# STM32U5A5 register map
File version: 1.8
CPU: CM33 r0p1, little endian, MPU, FPU, 4 interrupt priority bits
Registers are 32-bit, read-write, reset 0x0 unless marked. A register's access mark holds for its fields unless they carry their own. Offsets are from the block's base; [hi:lo] are bit positions; {n}, {i} and the like mark numbered series; 'fields as' and 'values as' point back to an identical list.

## GPDMA1 (part 2 of 2)
Base 0x40020000
Same registers: SEC_GPDMA1 0x50020000
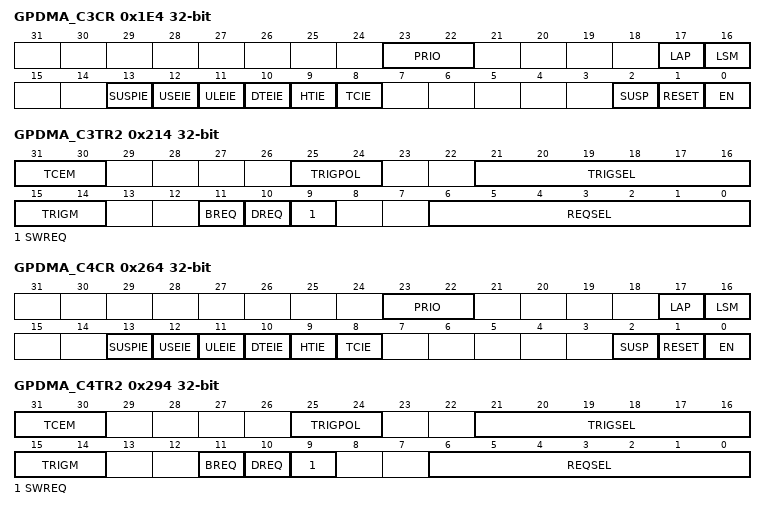
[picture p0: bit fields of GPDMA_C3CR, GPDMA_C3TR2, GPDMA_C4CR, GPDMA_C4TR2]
0x1E4 GPDMA_C3CR — channel x control register
  [23:22] PRIO — priority level of the DMA transfer of the channel x vs others- 00: low priority, low weight- 01: low priority, mid weight- 10: low priority, high weight- 11: high priorityNote: This bit must be written when EN=0. This bit is read-only when EN=1.
  [17] LAP — linked-list allocated portAllocate the master port for the update of the DMA linked-list registers from the memory.- 0: port 0 (AHB) is allocated for the update of the DMA linked-list channel x registers- 1: port 1 (AHB) is allocated for the update of the DMA linked-list channel x registersNote: This bit must be written when EN=0. This bit is read-only when EN=1.
  [16] LSM — Link Step mode:- 0: channel is executed for the full linked-list, and completed at the end (if any) of the last LLI i.e. when GPDMA_CxLLR=0: the 16 low significant bits of the link address are null (LA[15:0]=0) and all the update bits are null i.e. UT1=UB1=UT2=USA=UDA=UB2 =UT3=ULL=0. Then GPDMA_CxBR1.BRC[10:0]=0 and GPDMA_CxBR1.BNDT[15:0]=0.- 1: channel is executed once for the current LLI:* First the (possibly 2D/repeated) block transfer is executed as defined by the current internal register file until that (GPDMA_CxBR1.BRC[10:0]=0 and GPDMA_CxBR1.BNDT[15:0]=0).* Secondly the next linked-list data structure is conditionally uploaded from memory as defined by GPDMA_CxLLR register. Then channel execution is completed.Note: This bit must be written when EN=0. This bit is read-only when EN=1.
  [13] SUSPIE — completed suspension interrupt enable - 0: interrupt disabled - 1: interrupt enabled
  [12] USEIE — user setting error interrupt enable - 0: interrupt disabled - 1: interrupt enabled
  [11] ULEIE — update link transfer error interrupt enable - 0: interrupt disabled - 1: interrupt enabled
  [10] DTEIE — data transfer error interrupt enable - 0: interrupt disabled - 1: interrupt enabled
  [9] HTIE — half transfer complete interrupt enable - 0: interrupt disabled - 1: interrupt enabled
  [8] TCIE — transfer complete interrupt enable - 0: interrupt disabled - 1: interrupt enabled
  [2] SUSP — suspend - 0: write: resume channel, read: channel not suspended - 1: write: suspend channel, read: channel suspended Writing 1 into the field RESET (bit 1) causes the hardware to de-assert this bit, whatever is written into this bit 2. Else: Software must write 1 in order to suspend an active channel i.e. a channel with an on-going DMA transfer over its master ports. Software must write 0 in order to resume a suspended channel, following the programming sequence in Figure 3: DMA channel suspend and resume sequence.
  [1] RESET — reset - 0: no channel reset - 1: channel reset This bit is write only. Writing 0 has no impact. Writing 1 implies/will imply the reset of the FIFO, the reset of the channel internal state, and the reset of the SUSP and EN bits, whatever is written in respectively bit 2 and bit 0. The reset is/will be effective when the channel. i.e. either i) the active channel is in suspended state (i.e. GPDMA_CxSR.SUSPF=1 and GPDMA_CxSR.IDLEF=1 and GPDMA_CxCR.EN=1) or ii) the channel is in disabled state (i.e. GPDMA_CxSR.IDLEF=1 and GPDMA_CxCR.EN=0). After writing a RESET, if the user wants to continue using this channel, the user should explicitly reconfigure the channel including the hardware-modified configuration registers GPDMA_CxBR1, GPDMA_CxSAR and GPDMA_CxDAR, before enabling again the channel. Following the programming sequence in Figure 4: DMA channel abort and restart sequence.
  [0] EN — enable - 0: write: ignored, read: channel disabled - 1: write: enable channel, read: channel enabled Writing 1 into the field RESET (bit 1) causes the hardware to de-assert this bit, whatever is written into this bit 0. Else: * this bit is de-asserted by hardware when there is a transfer error (master bus error or user setting error) or when there is a channel transfer complete (channel ready to be configured, e.g. if LSM=1 at the end of a single execution of the LLI). * Else, this bit can be asserted by software. Writing 0 into this EN bit is ignored.
0x214 GPDMA_C3TR2 — GPDMA channel x transfer register 2
  [31:30] TCEM — Transfer complete event mode Defines the transfer granularity for the transfer complete (and half transfer complete) event generation. - 00: at block level (i.e. when GPDMA_CxBR1.BNDT[15:0]= 0): the complete (and the half) transfer event is generated at the (respectively half of the) end of a block. Note: If the initial LLI0 data transfer is null/void (i.e. directly programmed by the internal register file with GPDMA_CxBR1.BNDT[15:0]=0), then neither the complete transfer event nor the half transfer event is generated. - 01: channel x=0 to 11: same as 00 ;channel x=12 to 15: at 2D/repeated block level (i.e. when GPDMA_CxBR1.BRC[10:0]= 0 and GPDMA_CxBR1.BNDT[15:0]= 0): the complete (and the half) transfer event is generated at the end (respectively half of the end) of the 2D/repeated block Note: If the initial LLI0 data transfer is null/void (i.e. directly programmed by the internal register file with GPDMA_CxBR1.BNDT[15:0]=0), then neither the complete transfer event nor the half transfer event is generated. - 10: at LLI level: the complete transfer event is generated at the end of the LLI transfer, including the update of the LLI if any. The half transfer event is generated at the half of the LLI data transfer (the LLI data transfer being a block or a 2D/repeated block transfer), if any data transfer. Note: If the initial LLI0 data transfer is null/void (i.e. directly programmed by the internal register file with GPDMA_CxBR1.BNDT[15:0]=0), then the half transfer event is not generated, and the transfer complete event is generated when is completed the loading of the LLI1. - 11: at channel level: the complete transfer event is generated at the end of the last LLI transfer. The half transfer event is generated at the half of the data transfer of the last LLI. The last LLI is the one that updates the link address GPDMA_CxLLR.LA[15:2] to zero and that clears all the update bits - UT1, UT2, UB1, USA, UDA, if present UT3, UB2 and ULL - of the GPDMA_CxLLR register. If the channel transfer is continuous/infinite, no event is generated.
  [25:24] TRIGPOL — Trigger event polarity Defines the polarity of the selected trigger event input defined by TRIGSEL[5:0]. - 00: no trigger. Masked trigger event. - 01: trigger on the rising edge - 10: trigger on the falling edge - 11: same as 00
  [21:16] TRIGSEL — Trigger event input selection Note: Selects the trigger event input as per Table 13 of the DMA transfer, with an active trigger event if TRIGPOL[1:0] !=00.
  [15:14] TRIGM — Trigger mode
  [11] BREQ
  [10] DREQ — Destination hardware request If the channel x is activated (i.e. GPDMA_CxCR.EN is asserted) with SWREQ=1 (i.e. software request for a memory-to-memory transfer), this bit is ignored. Else: - 0: the selected hardware request is driven by a source peripheral (i.e. this request signal is taken into account by the DMA transfer scheduler over the source/read port) - 1: the selected hardware request is driven by a destination peripheral (.e. this request signal is taken into account by the DMA transfer scheduler over the destination/write port)
  [9] SWREQ — Software request When GPDMA_CxCR.EN is asserted, this field is internally taken into account: - 0: no software request. The selected hardware request REQSEL[6:0] is taken into account. - 1: software request (for a memory-to-memory transfer). And the default selected hardware request as per REQSEL[6:0] is ignored.
  [6:0] REQSEL — DMA hardware request selection If the channel x is activated (i.e. GPDMA_CxCR.EN is asserted) with SWREQ=1 (i.e. software request for a memory-to-memory transfer), this bit is ignored. Else, the selected hardware request as per Table 12 is internally taken into account. Note: The user must not assign a same input hardware request (i.e. a same REQSEL[6:0] value) to different active DMA channels (i.e. if GPDMA_CxCR.EN=1 and GPDMA_CxTR2.SWREQ=0 for the related x channels). In other words, DMA is not intended to hardware support the case of simultaneous enabled channels having been -incorrectly- configured with a same hardware peripheral request signal, and there is no user setting error reporting.
0x264 GPDMA_C4CR — channel x control register
  [23:22] PRIO — priority level of the DMA transfer of the channel x vs others- 00: low priority, low weight- 01: low priority, mid weight- 10: low priority, high weight- 11: high priorityNote: This bit must be written when EN=0. This bit is read-only when EN=1.
  [17] LAP — linked-list allocated portAllocate the master port for the update of the DMA linked-list registers from the memory.- 0: port 0 (AHB) is allocated for the update of the DMA linked-list channel x registers- 1: port 1 (AHB) is allocated for the update of the DMA linked-list channel x registersNote: This bit must be written when EN=0. This bit is read-only when EN=1.
  [16] LSM — Link Step mode:- 0: channel is executed for the full linked-list, and completed at the end (if any) of the last LLI i.e. when GPDMA_CxLLR=0: the 16 low significant bits of the link address are null (LA[15:0]=0) and all the update bits are null i.e. UT1=UB1=UT2=USA=UDA=UB2 =UT3=ULL=0. Then GPDMA_CxBR1.BRC[10:0]=0 and GPDMA_CxBR1.BNDT[15:0]=0.- 1: channel is executed once for the current LLI:* First the (possibly 2D/repeated) block transfer is executed as defined by the current internal register file until that (GPDMA_CxBR1.BRC[10:0]=0 and GPDMA_CxBR1.BNDT[15:0]=0).* Secondly the next linked-list data structure is conditionally uploaded from memory as defined by GPDMA_CxLLR register. Then channel execution is completed.Note: This bit must be written when EN=0. This bit is read-only when EN=1.
  [13] SUSPIE — completed suspension interrupt enable - 0: interrupt disabled - 1: interrupt enabled
  [12] USEIE — user setting error interrupt enable - 0: interrupt disabled - 1: interrupt enabled
  [11] ULEIE — update link transfer error interrupt enable - 0: interrupt disabled - 1: interrupt enabled
  [10] DTEIE — data transfer error interrupt enable - 0: interrupt disabled - 1: interrupt enabled
  [9] HTIE — half transfer complete interrupt enable - 0: interrupt disabled - 1: interrupt enabled
  [8] TCIE — transfer complete interrupt enable - 0: interrupt disabled - 1: interrupt enabled
  [2] SUSP — suspend - 0: write: resume channel, read: channel not suspended - 1: write: suspend channel, read: channel suspended Writing 1 into the field RESET (bit 1) causes the hardware to de-assert this bit, whatever is written into this bit 2. Else: Software must write 1 in order to suspend an active channel i.e. a channel with an on-going DMA transfer over its master ports. Software must write 0 in order to resume a suspended channel, following the programming sequence in Figure 3: DMA channel suspend and resume sequence.
  [1] RESET
  [0] EN — enable - 0: write: ignored, read: channel disabled - 1: write: enable channel, read: channel enabled Writing 1 into the field RESET (bit 1) causes the hardware to de-assert this bit, whatever is written into this bit 0. Else: * this bit is de-asserted by hardware when there is a transfer error (master bus error or user setting error) or when there is a channel transfer complete (channel ready to be configured, e.g. if LSM=1 at the end of a single execution of the LLI). * Else, this bit can be asserted by software. Writing 0 into this EN bit is ignored.
0x294 GPDMA_C4TR2 — GPDMA channel x transfer register 2
  [31:30] TCEM — Transfer complete event mode
  [25:24] TRIGPOL — Trigger event polarity Defines the polarity of the selected trigger event input defined by TRIGSEL[5:0]. - 00: no trigger. Masked trigger event. - 01: trigger on the rising edge - 10: trigger on the falling edge - 11: same as 00
  [21:16] TRIGSEL — Trigger event input selection Note: Selects the trigger event input as per Table 13 of the DMA transfer, with an active trigger event if TRIGPOL[1:0] !=00.
  [15:14] TRIGM — Trigger mode: rst read of a/each block transfer is conditioned by one hit trigger.
  [11] BREQ
  [10] DREQ — Destination hardware request If the channel x is activated (i.e. GPDMA_CxCR.EN is asserted) with SWREQ=1 (i.e. software request for a memory-to-memory transfer), this bit is ignored. Else: - 0: the selected hardware request is driven by a source peripheral (i.e. this request signal is taken into account by the DMA transfer scheduler over the source/read port) - 1: the selected hardware request is driven by a destination peripheral (.e. this request signal is taken into account by the DMA transfer scheduler over the destination/write port)
  [9] SWREQ — Software request When GPDMA_CxCR.EN is asserted, this field is internally taken into account: - 0: no software request. The selected hardware request REQSEL[6:0] is taken into account. - 1: software request (for a memory-to-memory transfer). And the default selected hardware request as per REQSEL[6:0] is ignored.
  [6:0] REQSEL — DMA hardware request selection If the channel x is activated (i.e. GPDMA_CxCR.EN is asserted) with SWREQ=1 (i.e. software request for a memory-to-memory transfer), this bit is ignored. Else, the selected hardware request as per Table 12 is internally taken into account. Note: The user must not assign a same input hardware request (i.e. a same REQSEL[6:0] value) to different active DMA channels (i.e. if GPDMA_CxCR.EN=1 and GPDMA_CxTR2.SWREQ=0 for the related x channels). In other words, DMA is not intended to hardware support the case of simultaneous enabled channels having been -incorrectly- configured with a same hardware peripheral request signal, and there is no user setting error reporting.
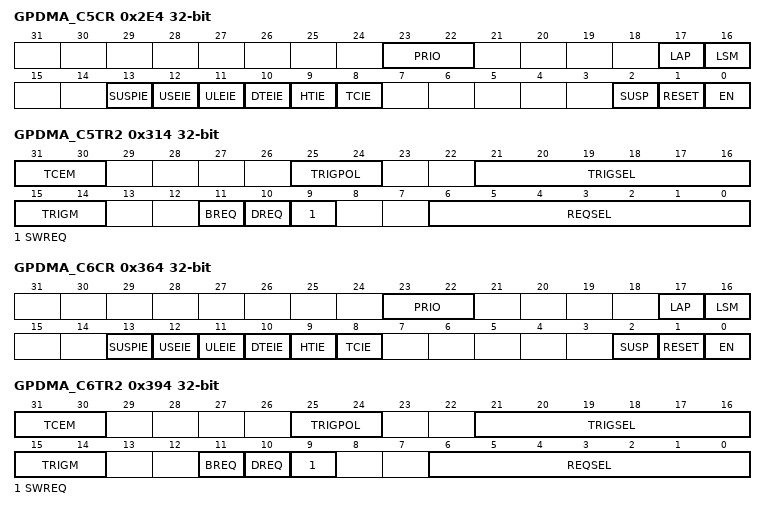
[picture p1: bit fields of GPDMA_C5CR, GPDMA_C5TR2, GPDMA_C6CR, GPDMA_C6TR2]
0x2E4 GPDMA_C5CR — channel x control register
  [23:22] PRIO — priority level of the DMA transfer of the channel x vs others- 00: low priority, low weight- 01: low priority, mid weight- 10: low priority, high weight- 11: high priorityNote: This bit must be written when EN=0. This bit is read-only when EN=1.
  [17] LAP — linked-list allocated portAllocate the master port for the update of the DMA linked-list registers from the memory.- 0: port 0 (AHB) is allocated for the update of the DMA linked-list channel x registers- 1: port 1 (AHB) is allocated for the update of the DMA linked-list channel x registersNote: This bit must be written when EN=0. This bit is read-only when EN=1.
  [16] LSM — Link Step mode:- 0: channel is executed for the full linked-list, and completed at the end (if any) of the last LLI i.e. when GPDMA_CxLLR=0: the 16 low significant bits of the link address are null (LA[15:0]=0) and all the update bits are null i.e. UT1=UB1=UT2=USA=UDA=UB2 =UT3=ULL=0. Then GPDMA_CxBR1.BRC[10:0]=0 and GPDMA_CxBR1.BNDT[15:0]=0.- 1: channel is executed once for the current LLI:* First the (possibly 2D/repeated) block transfer is executed as defined by the current internal register file until that (GPDMA_CxBR1.BRC[10:0]=0 and GPDMA_CxBR1.BNDT[15:0]=0).* Secondly the next linked-list data structure is conditionally uploaded from memory as defined by GPDMA_CxLLR register. Then channel execution is completed.Note: This bit must be written when EN=0. This bit is read-only when EN=1.
  [13] SUSPIE — completed suspension interrupt enable - 0: interrupt disabled - 1: interrupt enabled
  [12] USEIE — user setting error interrupt enable - 0: interrupt disabled - 1: interrupt enabled
  [11] ULEIE — update link transfer error interrupt enable - 0: interrupt disabled - 1: interrupt enabled
  [10] DTEIE — data transfer error interrupt enable - 0: interrupt disabled - 1: interrupt enabled
  [9] HTIE — half transfer complete interrupt enable - 0: interrupt disabled - 1: interrupt enabled
  [8] TCIE — transfer complete interrupt enable - 0: interrupt disabled - 1: interrupt enabled
  [2] SUSP — suspend - 0: write: resume channel, read: channel not suspended - 1: write: suspend channel, read: channel suspended Writing 1 into the field RESET (bit 1) causes the hardware to de-assert this bit, whatever is written into this bit 2. Else: Software must write 1 in order to suspend an active channel i.e. a channel with an on-going DMA transfer over its master ports. Software must write 0 in order to resume a suspended channel, following the programming sequence in Figure 3: DMA channel suspend and resume sequence.
  [1] RESET — reset - 0: no channel reset - 1: channel reset This bit is write only. Writing 0 has no impact. Writing 1 implies/will imply the reset of the FIFO, the reset of the channel internal state, and the reset of the SUSP and EN bits, whatever is written in respectively bit 2 and bit 0. The reset is/will be effective when the channel is in state i.e. either i) the active channel is in suspended state (i.e. GPDMA_CxSR.SUSPF=1 and GPDMA_CxSR.IDLEF=1 and GPDMA_CxCR.EN=1) or ii) the channel is in disabled state (i.e. GPDMA_CxSR.IDLEF=1 and GPDMA_CxCR.EN=0). After writing a RESET, if the user wants to continue using this channel, the user should explicitly reconfigure the channel including the hardware-modified configuration registers GPDMA_CxBR1, GPDMA_CxSAR and GPDMA_CxDAR, before enabling again the channel. Following the programming sequence in Figure 4: DMA channel abort and restart sequence.
  [0] EN — enable - 0: write: ignored, read: channel disabled - 1: write: enable channel, read: channel enabled Writing 1 into the field RESET (bit 1) causes the hardware to de-assert this bit, whatever is written into this bit 0. Else: * this bit is de-asserted by hardware when there is a transfer error (master bus error or user setting error) or when there is a channel transfer complete (channel ready to be configured, e.g. if LSM=1 at the end of a single execution of the LLI). * Else, this bit can be asserted by software. Writing 0 into this EN bit is ignored.
0x314 GPDMA_C5TR2 — GPDMA channel x transfer register 2
  fields as GPDMA_C3TR2
0x364 GPDMA_C6CR — channel x control register
  fields as GPDMA_C5CR
0x394 GPDMA_C6TR2 — GPDMA channel x transfer register 2
  [31:30] TCEM — Transfer complete event mode Defines the transfer granularity for the transfer complete (and half transfer complete) event generation. - 00: at block level (i.e. when GPDMA_CxBR1.BNDT[15:0]= 0): the complete (and the half) transfer event is generated at the (respectively half of the) end of a block. Note: If the initial LLI0 data transfer is null/void (i.e. directly programmed by the internal register file with GPDMA_CxBR1.BNDT[15:0]=0), then neither the complete transfer event nor the half transfer event is generated. - 01: channel x=0 to 11: same as 00 ;channel x=12 to 15: at 2D/repeated block level (i.e. when GPDMA_CxBR1.BRC[10:0]= 0 and GPDMA_CxBR1.BNDT[15:0]= 0): the complete (and the half) transfer event is generated at the end (respectively half of the end) of the 2D/repeated block Note: If the initial LLI0 data transfer is null/void (i.e. directly programmed by the internal register file with GPDMA_CxBR1.BNDT[15:0]=0), then neither the complete transfer event nor the half transfer event is generated. - 10: at LLI level: the complete transfer event is generated at the end of the LLI transfer, including the update of the LLI if any. The half transfer event is generated at the half of the LLI data transfer (the LLI data transfer being a block or a 2D/repeated block transfer), if any data transfer. Note: If the initial LLI0 data transfer is null/void (i.e. directly programmed by the internal register file with GPDMA_CxBR1.BNDT[15:0]=0), then the half transfer event is not generated, and the transfer complete event is generated when is completed the loading of the LLI1. - 11: at channel level: the complete transfer event is generated at the end of the last LLI transfer. The half transfer event is generated at the half of the data transfer of the last LLI. The last LLI is the one that updates the link address GPDMA_CxLLR.LA[15:2] to zero and that clears all the update bits - UT1, UT2, UB1, USA, UDA, if present UT3, UB2 and ULL - of the GPDMA_CxLLR register. If the channel transfer is continuous/infinite, no event is generated.
  [25:24] TRIGPOL — Trigger event polarity Defines the polarity of the selected trigger event input defined by TRIGSEL[5:0]. - 00: no trigger. Masked trigger event. - 01: trigger on the rising edge - 10: trigger on the falling edge - 11: same as 00
  [21:16] TRIGSEL — Trigger event input selection Note: Selects the trigger event input as per Table 13 of the DMA transfer, with an active trigger event if TRIGPOL[1:0] !=00.
  [15:14] TRIGM — Trigger mode: Defines the transfer granularity for its conditioning by the trigger. If the channel x is enabled (i.e. when GPDMA_CxCR.EN is asserted) with TRIGPOL[1:0]=00 or 11, these bits are ignored. Else, a DMA transfer is conditioned by (at least) one trigger hit, either at: - 00: at block level (for channel x=12 to 15: for each block if a 2D/repeated block is configured i.e. if GPDMA_CxBR1.BRC[10:0]! = 0): the first burst read of a/each block transfer is conditioned by one hit trigger. - 01: at 2D/repeated block level for channel x=12 to 15; same as 00 for channel x=0 to 11
  [11] BREQ
  [10] DREQ — Destination hardware request If the channel x is activated (i.e. GPDMA_CxCR.EN is asserted) with SWREQ=1 (i.e. software request for a memory-to-memory transfer), this bit is ignored. Else: - 0: the selected hardware request is driven by a source peripheral (i.e. this request signal is taken into account by the DMA transfer scheduler over the source/read port) - 1: the selected hardware request is driven by a destination peripheral (.e. this request signal is taken into account by the DMA transfer scheduler over the destination/write port)
  [9] SWREQ — Software request When GPDMA_CxCR.EN is asserted, this field is internally taken into account: - 0: no software request. The selected hardware request REQSEL[6:0] is taken into account. - 1: software request (for a memory-to-memory transfer). And the default selected hardware request as per REQSEL[6:0] is ignored.
  [6:0] REQSEL — DMA hardware request selection If the channel x is activated (i.e. GPDMA_CxCR.EN is asserted) with SWREQ=1 (i.e. software request for a memory-to-memory transfer), this bit is ignored. Else, the selected hardware request as per Table 12 is internally taken into account. Note: The user must not assign a same input hardware request (i.e. a same REQSEL[6:0] value) to different active DMA channels (i.e. if GPDMA_CxCR.EN=1 and GPDMA_CxTR2.SWREQ=0 for the related x channels). In other words, DMA is not intended to hardware support the case of simultaneous enabled channels having been -incorrectly- configured with a same hardware peripheral request signal, and there is no user setting error reporting.
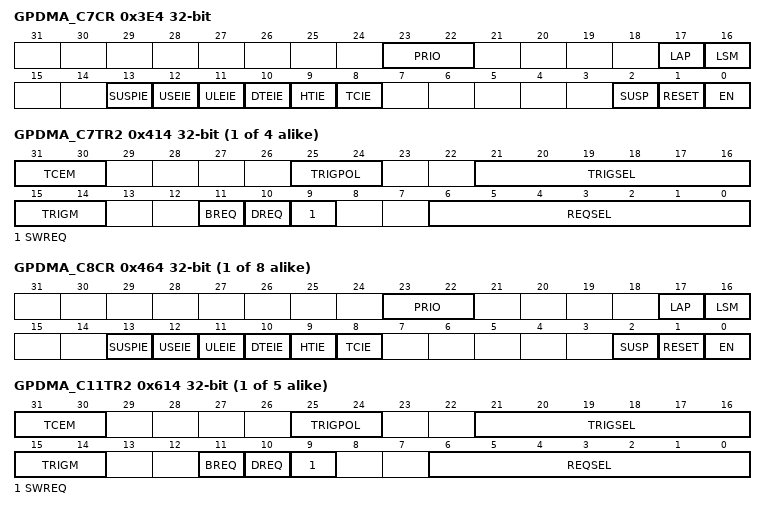
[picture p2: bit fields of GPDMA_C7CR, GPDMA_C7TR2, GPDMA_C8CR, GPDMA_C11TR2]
0x3E4 GPDMA_C7CR — channel x control register
  fields as GPDMA_C4CR
{0x94+0x80*i} GPDMA_C{i}TR2 (i=7..10) — GPDMA channel x transfer register 2
  [31:30] TCEM — Transfer complete event mode Defines the transfer granularity for the transfer complete (and half transfer complete) event generation. - 00: at block level (i.e. when GPDMA_CxBR1.BNDT[15:0]= 0): the complete (and the half) transfer event is generated at the (respectively half of the) end of a block. Note: If the initial LLI0 data transfer is null/void (i.e. directly programmed by the internal register file with GPDMA_CxBR1.BNDT[15:0]=0), then neither the complete transfer event nor the half transfer event is generated. - 01: channel x=0 to 11: same as 00 ;channel x=12 to 15: at 2D/repeated block level (i.e. when GPDMA_CxBR1.BRC[10:0]= 0 and GPDMA_CxBR1.BNDT[15:0]= 0): the complete (and the half) transfer event is generated at the end (respectively half of the end) of the 2D/repeated block Note: If the initial LLI0 data transfer is null/void (i.e. directly programmed by the internal register file with GPDMA_CxBR1.BNDT[15:0]=0), then neither the complete transfer event nor the half transfer event is generated. - 10: at LLI level: the complete transfer event is generated at the end of the LLI transfer, including the update of the LLI if any. The half transfer event is generated at the half of the LLI data transfer (the LLI data transfer being a block or a 2D/repeated block transfer), if any data transfer. Note: If the initial LLI0 data transfer is null/void (i.e. directly programmed by the internal register file with GPDMA_CxBR1.BNDT[15:0]=0), then the half transfer event is not generated, and the transfer complete event is generated when is completed the loading of the LLI1. - 11: at channel level: the complete transfer event is generated at the end of the last LLI transfer. The half transfer event is generated at the half of the data transfer of the last LLI. The last LLI is the one that updates the link address GPDMA_CxLLR.LA[15:2] to zero and that clears all the update bits - UT1, UT2, UB1, USA, UDA, if present UT3, UB2 and ULL - of the GPDMA_CxLLR register. If the channel transfer is continuous/infinite, no event is generated.
  [25:24] TRIGPOL — Trigger event polarity Defines the polarity of the selected trigger event input defined by TRIGSEL[5:0]. - 00: no trigger. Masked trigger event. - 01: trigger on the rising edge - 10: trigger on the falling edge - 11: same as 00
  [21:16] TRIGSEL — Trigger event input selection Note: Selects the trigger event input as per Table 13 of the DMA transfer, with an active trigger event if TRIGPOL[1:0] !=00.
  [15:14] TRIGM — Trigger mode: Defines the transfer granularity for its conditioning by the trigger. If the channel x is enabled (i.e. when GPDMA_CxCR.EN is asserted) with TRIGPOL[1:0]=00 or 11, these bits are ignored. Else, a DMA transfer is conditioned by (at least) one trigger hit, either at: - 00: at block level (for channel x=12 to 15: for each block if a 2D/repeated block is configured i.e. if GPDMA_CxBR1.BRC[10:0]! = 0): the first burst read of a/each block transfer is conditioned by one hit trigger. - 01: at 2D/repeated block level for channel x=12 to 15; same as 00 for channel x=0 to 11: the first burst read of a 2D/repeated block transfer is conditioned by one hit trigger.
  [11] BREQ
  [10] DREQ — Destination hardware request If the channel x is activated (i.e. GPDMA_CxCR.EN is asserted) with SWREQ=1 (i.e. software request for a memory-to-memory transfer), this bit is ignored. Else: - 0: the selected hardware request is driven by a source peripheral (i.e. this request signal is taken into account by the DMA transfer scheduler over the source/read port) - 1: the selected hardware request is driven by a destination peripheral (.e. this request signal is taken into account by the DMA transfer scheduler over the destination/write port)
  [9] SWREQ — Software request When GPDMA_CxCR.EN is asserted, this field is internally taken into account: - 0: no software request. The selected hardware request REQSEL[6:0] is taken into account. - 1: software request (for a memory-to-memory transfer). And the default selected hardware request as per REQSEL[6:0] is ignored.
  [6:0] REQSEL — DMA hardware request selection If the channel x is activated (i.e. GPDMA_CxCR.EN is asserted) with SWREQ=1 (i.e. software request for a memory-to-memory transfer), this bit is ignored. Else, the selected hardware request as per Table 12 is internally taken into account. Note: The user must not assign a same input hardware request (i.e. a same REQSEL[6:0] value) to different active DMA channels (i.e. if GPDMA_CxCR.EN=1 and GPDMA_CxTR2.SWREQ=0 for the related x channels). In other words, DMA is not intended to hardware support the case of simultaneous enabled channels having been -incorrectly- configured with a same hardware peripheral request signal, and there is no user setting error reporting.
{0x64+0x80*i} GPDMA_C{i}CR (i=8..15) — channel x control register
  fields as GPDMA_C5CR
{0x94+0x80*i} GPDMA_C{i}TR2 (i=11..15) — GPDMA channel x transfer register 2
  [31:30] TCEM — Transfer complete event mode Defines the transfer granularity for the transfer complete (and half transfer complete) event generation. - 00: at block level (i.e. when GPDMA_CxBR1.BNDT[15:0]= 0): the complete (and the half) transfer event is generated at the (respectively half of the) end of a block. Note: If the initial LLI0 data transfer is null/void (i.e. directly programmed by the internal register file with GPDMA_CxBR1.BNDT[15:0]=0), then neither the complete transfer event nor the half transfer event is generated. - 01: channel x=0 to 11: same as 00 ;channel x=12 to 15: at 2D/repeated block level (i.e. when GPDMA_CxBR1.BRC[10:0]= 0 and GPDMA_CxBR1.BNDT[15:0]= 0): the complete (and the half) transfer event is generated at the end (respectively half of the end) of the 2D/repeated block Note: If the initial LLI0 data transfer is null/void (i.e. directly programmed by the internal register file with GPDMA_CxBR1.BNDT[15:0]=0), then neither the complete transfer event nor the half transfer event is generated. - 10: at LLI level: the complete transfer event is generated at the end of the LLI transfer, including the update of the LLI if any. The half transfer event is generated at the half of the LLI data transfer (the LLI data transfer being a block or a 2D/repeated block transfer), if any data transfer. Note: If the initial LLI0 data transfer is null/void (i.e. directly programmed by the internal register file with GPDMA_CxBR1.BNDT[15:0]=0), then the half transfer event is not generated, and the transfer complete event is generated when is completed the loading of the LLI1. - 11: at channel level: the complete transfer event is generated at the end of the last LLI transfer. The half transfer event is generated at the half of the data transfer of the last LLI. The last LLI is the one that updates the link address GPDMA_CxLLR.LA[15:2] to zero and that clears all the update bits - UT1, UT2, UB1, USA, UDA, if present UT3, UB2 and ULL - of the GPDMA_CxLLR register. If the channel transfer is continuous/infinite, no event is generated.
  [25:24] TRIGPOL — Trigger event polarity Defines the polarity of the selected trigger event input defined by TRIGSEL[5:0]. - 00: no trigger. Masked trigger event. - 01: trigger on the rising edge - 10: trigger on the falling edge - 11: same as 00
  [21:16] TRIGSEL — Trigger event input selection Note: Selects the trigger event input as per Table 13 of the DMA transfer, with an active trigger event if TRIGPOL[1:0] !=00.
  [15:14] TRIGM — Trigger mode: enabled. Transferring a next LLIn+1 which updates the GPDMA_CxTR2 with a new value for any of TRIGSEL[5:0] or TRIGPOL[1:0] resets the monitoring, trashing the (possible) memorized hit of the formerly defined LLIn trigger. After that a first new trigger hitn+1 is memorized, if another second trigger hitn+2 is detected and if the hitn triggered transfer is still not completed, this new second trigger hitn+2 is lost and not memorized. Note: When the source block size is not a multiple of the source burst size and is a multiple of the source data width, then the last programmed source burst is not completed and is internally shorten to match the block size. In this case, if TRIGM[1:0]=11 and (SWREQ=1 or (SWREQ=0 and DREQ=0)), the shortened burst transfer (by single(s) or/and by burst(s) of lower length) is conditioned once by the trigger. Note: When the programmed destination burst is internally shortened by single(s) or/and by burst(s) of lower length (e.g. vs FIFO size, vs block size, 1kB/4kB boundary address crossing): if the trigger is conditioning the programmed destination burst (if TRIGM[1:0]=11 and SWREQ=0 and DREQ=1), this shortened destination burst transfer is conditioned once by the trigger.
  [11] BREQ
  [10] DREQ — Destination hardware request If the channel x is activated (i.e. GPDMA_CxCR.EN is asserted) with SWREQ=1 (i.e. software request for a memory-to-memory transfer), this bit is ignored. Else: - 0: the selected hardware request is driven by a source peripheral (i.e. this request signal is taken into account by the DMA transfer scheduler over the source/read port) - 1: the selected hardware request is driven by a destination peripheral (.e. this request signal is taken into account by the DMA transfer scheduler over the destination/write port)
  [9] SWREQ — Software request When GPDMA_CxCR.EN is asserted, this field is internally taken into account: - 0: no software request. The selected hardware request REQSEL[6:0] is taken into account. - 1: software request (for a memory-to-memory transfer). And the default selected hardware request as per REQSEL[6:0] is ignored.
  [6:0] REQSEL — DMA hardware request selection If the channel x is activated (i.e. GPDMA_CxCR.EN is asserted) with SWREQ=1 (i.e. software request for a memory-to-memory transfer), this bit is ignored. Else, the selected hardware request as per Table 12 is internally taken into account. Note: The user must not assign a same input hardware request (i.e. a same REQSEL[6:0] value) to different active DMA channels (i.e. if GPDMA_CxCR.EN=1 and GPDMA_CxTR2.SWREQ=0 for the related x channels). In other words, DMA is not intended to hardware support the case of simultaneous enabled channels having been -incorrectly- configured with a same hardware peripheral request signal, and there is no user setting error reporting.
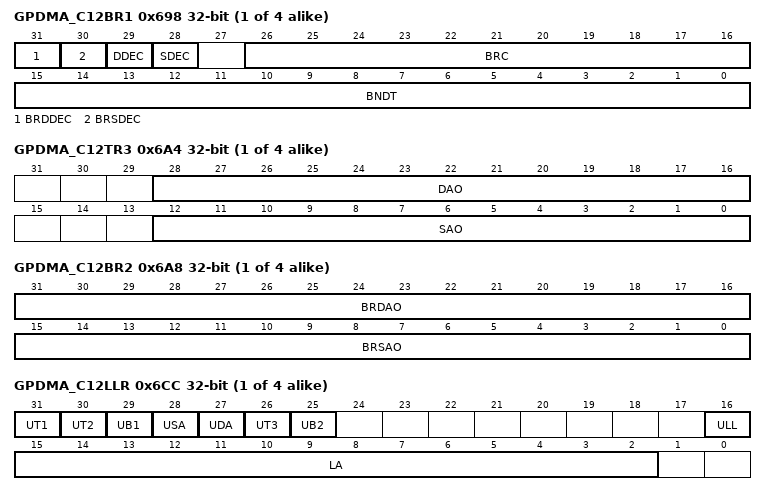
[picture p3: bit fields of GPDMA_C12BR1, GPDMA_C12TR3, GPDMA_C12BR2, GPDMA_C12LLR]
{0x98+0x80*i} GPDMA_C{i}BR1 (i=12..15) — GPDMA channel x block register 1
  [31] BRDDEC
  [30] BRSDEC
  [29] DDEC
  [28] SDEC
  [26:16] BRC
  [15:0] BNDT — block number of data bytes to transfer from the source
{0xA4+0x80*i} GPDMA_C{i}TR3 (i=12..15) — GPDMA channel x transfer register 3
  [28:16] DAO — destination address offset increment The destination address, pointed by GPDMA_CxDAR, is incremented or decremented (depending on GPDMA_CxBR1.DDEC) by this offset DAO[12:0] for each programmed destination burst. This offset is not including and is added to the programmed burst size when the completed burst is addressed in incremented mode i.e. if GPDMA_CxTR1.DINC=1. Note: A destination address offset must be aligned with the programmed data width of a destination burst (c.f. DAO[2:0] vs GPDMA_CxTR1.DDW_LOG2[1:0]). Else a user setting error is reported and none transfer is issued. Note: When the source block size is not a multiple of the destination burst size and is a multiple of the source data width, then the last programmed source burst is not completed and is internally shorten to match the block size. In this case, the additional GPDMA_CxTR3.SAO[12:0] is not applied.
  [12:0] SAO — source address offset increment The source address, pointed by GPDMA_CxSAR, is incremented or decremented (depending on GPDMA_CxBR1.SDEC) by this offset SAO[12:0] for each programmed source burst. This offset is not including and is added to the programmed burst size when the completed burst is addressed in incremented mode i.e. if GPDMA_CxTR1.SINC=1. Note: A source address offset must be aligned with the programmed data width of a source burst (c.f. SAO[2:0] vs GPDMA_CxTR1.SDW_LOG2[1:0]). Else a user setting error is reported and none transfer is issued.
{0xA8+0x80*i} GPDMA_C{i}BR2 (i=12..15) — GPDMA channel x block register 2
  [31:16] BRDAO — Block repeated destination address offset For a channel with 2D addressing capability, this field BRDAO[15:0] is used to update (by addition or subtraction depending on GPDMA_CxBR1.BRDDEC) the current destination address (i.e. GPDMA_CxDAR) at the end of a block transfer. Note: A block repeated destination address offset must be aligned with the programmed data width of a destination burst (c.f. BRDAO[2:0] vs GPDMA_CxTR1.DDW_LOG2[1:0]). Else a user setting error is reported and none transfer is issued.
  [15:0] BRSAO — Block repeated source address offset For a channel with 2D addressing capability, this field BRSAO[15:0] is used to update (by addition or subtraction depending on GPDMA_CxBR1.BRSDEC) the current source address (i.e. GPDMA_CxSAR) at the end of a block transfer. Note: A block repeated source address offset must be aligned with the programmed data width of a source burst (c.f. BRSAO[2:0] vs GPDMA_CxTR1.SDW_LOG2[1:0]). Else a user setting error is reported and none transfer is issued.
{0xCC+0x80*i} GPDMA_C{i}LLR (i=12..15) — GPDMA channel x linked-list address register
  [31] UT1 — Update GPDMA_CxTR1 from memory This bit controls the update of the GPDMA_CxTR1 register from the memory during the link transfer. - 0: no GPDMA_CxTR1 update - 1: GPDMA_CxTR1 update
  [30] UT2 — Update GPDMA_CxTR2 from memory This bit controls the update of the GPDMA_CxTR2 register from the memory during the link transfer. - 0: no GPDMA_CxTR2 update - 1: GPDMA_CxTR2 update
  [29] UB1 — Update GPDMA_CxBR1 from memory This bit controls the update of the GPDMA_CxBR1 register from the memory during the link transfer. If UB1=0 and if GPDMA_CxLLR != 0, the linked-list is not completed. Then GPDMA_CxBR1.BNDT[15:0] is restored to the programmed value after data transfer is completed and before the link transfer. - 0: no GPDMA_CxBR1 update (GPDMA_CxBR1.BNDT[15:0] is restored, if any link transfer) - 1: GPDMA_CxBR1 update
  [28] USA — Update GPDMA_CxSAR from memory This bit controls the update of the GPDMA_CxSAR register from the memory during the link transfer. - 0: no GPDMA_CxSAR update - 1: GPDMA_CxSAR update
  [27] UDA — Update GPDMA_CxDAR from memory This bit controls the update of the GPDMA_CxDAR register from the memory during the link transfer. - 0: no GPDMA_CxDAR update - 1: GPDMA_CxDAR update
  [26] UT3 — Update GPDMA_CxTR3 from memory This bit controls the update of the GPDMA_CxTR3 register from the memory during the link transfer. - 0: no GPDMA_CxTR3 update - 1: GPDMA_CxTR3 update
  [25] UB2 — Update GPDMA_CxBR2 from memory This bit controls the update of the GPDMA_CxBR2 register from the memory during the link transfer. - 0: no GPDMA_CxBR2 update - 1: GPDMA_CxBR2 update
  [16] ULL — Update GPDMA_CxLLR from memory This bit controls the update of the GPDMA_CxLLR register from the memory during the link transfer. - 0: no GPDMA_CxLLR update - 1: GPDMA_CxLLR update
  [15:2] LA — pointer (16-bit low significant address) to the next linked-list data structure If UT1=UT2=UB1=USA=UDA=ULL=0 and if LA[15:2]=0: the current LLI is the last one. The channel transfer is completed without any update of the linked-list DMA register file. Else, this field is the pointer to the memory address offset from which the next linked-list data structure will be automatically fetched from, once the data transfer is completed, in order to conditionally update the linked-list DMA internal register file i.e. possibly GPDMA_CxCTR1, GPDMA_CxTR2, GPDMA_CxBR1, GPDMA_CxSAR, GPDMA_CxDAR and GPDMA_CxLLR. Note: The user should program the pointer to be 32-bit aligned. The two low significant bits are write ignored.

## Notices in the file
Copyright (c) 2025 STMicroelectronics.
SPDX-License-Identifier: Apache-2.0
Licensed under the Apache License, Version 2.0 (the "License");
you may not use this file except in compliance with the License.
You may obtain a copy of the License at
http://www.apache.org/licenses/LICENSE-2.0
Unless required by applicable law or agreed to in writing, software
distributed under the License is distributed on an "AS IS" BASIS,
WITHOUT WARRANTIES OR CONDITIONS OF ANY KIND, either express or implied.
See the License for the specific language governing permissions and
limitations under the License.
